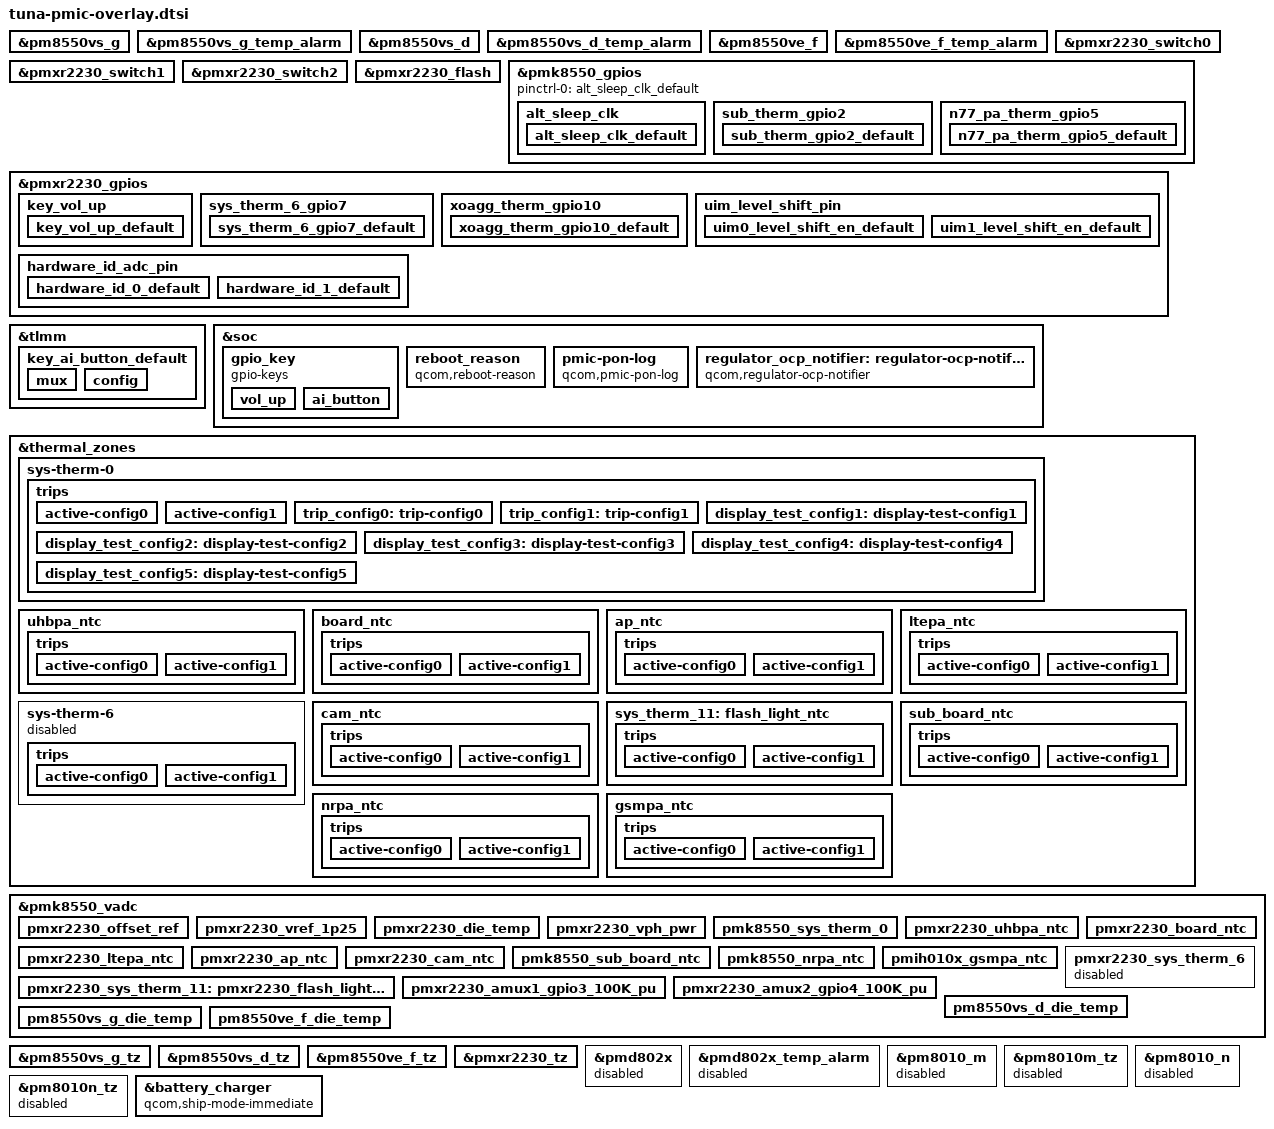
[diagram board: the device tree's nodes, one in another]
// SPDX-License-Identifier: BSD-3-Clause
/*
 * Copyright (c) 2024-2025, Qualcomm Innovation Center, Inc. All rights reserved.
 */

#include <dt-bindings/gpio/gpio.h>
#include <dt-bindings/iio/qcom,spmi-adc5-gen3-pmxr2230.h>
#include <dt-bindings/iio/qcom,spmi-adc5-gen4-pmih010x.h>

#include "pmk8550.dtsi"
#include "pmxr2230.dtsi"
#include "pm8550vs.dtsi"
#include "pmr735d.dtsi"
#include "pm8550ve.dtsi"
#include "pm8010.dtsi"
#include "pmd802x.dtsi"

&pm8550vs_g {
	status = "ok";
};

&pm8550vs_g_temp_alarm {
	status = "ok";
};

&pm8550vs_d {
	status = "ok";
};

&pm8550vs_d_temp_alarm {
	status = "ok";
};

&pm8550ve_f {
	status = "ok";
};

&pm8550ve_f_temp_alarm {
	status = "ok";
};

&pmxr2230_switch0 {
	qcom,led-mask = <9>; /* Channels 1 & 4 */
	qcom,symmetry-en;
};

&pmxr2230_switch1 {
	qcom,led-mask = <6>; /* Channels 2 & 3 */
	qcom,symmetry-en;
};

&pmxr2230_switch2 {
	qcom,led-mask = <15>; /* All Channels */
	qcom,symmetry-en;
};

&pmxr2230_flash {
	status = "ok";
};

&pmk8550_gpios {
	pinctrl-0 = <&alt_sleep_clk_default>;
	pinctrl-names = "default";

	alt_sleep_clk {
		alt_sleep_clk_default: alt_sleep_clk_default {
			pins = "gpio3";
			function = "func1";
			input-disable;
			output-enable;
			bias-disable;
			power-source = <0>;
		};
	};

	sub_therm_gpio2 {
		sub_therm_gpio2_default: sub_therm_gpio2_default {
			pins = "gpio2";
			bias-high-impedance;
		};
	};

	n77_pa_therm_gpio5 {
		n77_pa_therm_gpio5_default: n77_pa_therm_gpio5_default {
			pins = "gpio5";
			bias-high-impedance;
		};
	};
};

&pmxr2230_gpios {
	pinctrl-names = "default";
	pinctrl-0 = <&uim0_level_shift_en_default
				 &uim1_level_shift_en_default>;

	key_vol_up {
		key_vol_up_default: key_vol_up_default {
			pins = "gpio6";
			function = "normal";
			input-enable;
			bias-pull-up;
			power-source = <1>;
		};
	};

	sys_therm_6_gpio7 {
		sys_therm_6_gpio7_default: sys_therm_6_gpio7_default {
			pins = "gpio7";
			bias-high-impedance;
		};
	};

	xoagg_therm_gpio10 {
		xoagg_therm_gpio10_default: xoagg_therm_gpio10_default {
			pins = "gpio10";
			bias-high-impedance;
		};
	};

	uim_level_shift_pin {
		uim0_level_shift_en_default: uim0_level_shift_en_default {
			pins = "gpio1";
			function = "normal";
			power-source = <1>;
			bias-disable;
			input-disable;
			output-high;
		};
		uim1_level_shift_en_default: uim1_level_shift_en_default {
			pins = "gpio2";
			function = "normal";
			power-source = <1>;
			bias-disable;
			input-disable;
			output-high;
		 };
	};

	hardware_id_adc_pin {
		/* HWID ID_0: Build ID */
		hardware_id_0_default: hardware_id_0_default {
			pins = "gpio4";
			bias-high-impedance;
		};
		/* HWID ID_1: Project ID */
		hardware_id_1_default: hardware_id_1_default {
			pins = "gpio3";
			bias-high-impedance;
		};
	};
};

&tlmm {
	key_ai_button_default: key_ai_button_default {
		mux {
			pins = "gpio78";
			function = "gpio";
		};

		config {
			pins = "gpio78";
			bias-pull-up;
			input-enable;
		};
	};
};

&soc {
	gpio_key {
		compatible = "gpio-keys";
		label = "gpio-keys";
		pinctrl-names = "default";
		pinctrl-0 = <&key_vol_up_default &key_ai_button_default>;
		vol_up {
			label = "volume_up";
			gpios = <&pmxr2230_gpios 6 GPIO_ACTIVE_LOW>;
			linux,input-type = <1>;
			linux,code = <KEY_VOLUMEUP>;
			gpio-key,wakeup;
			debounce-interval = <15>;
			linux,can-disable;
		};

		ai_button {
			label = "ai_button";
			gpios = <&tlmm 78 GPIO_ACTIVE_LOW>;
			linux,input-type = <1>;
			linux,code = <250>; /* KEY_AI */
			gpio-key,wakeup;
			debounce-interval = <15>;
			linux,can-disable;
		};
	};

	reboot_reason {
		compatible = "qcom,reboot-reason";
		nvmem-cells = <&restart_reason>;
		nvmem-cell-names = "restart_reason";
	};

	pmic-pon-log {
		compatible = "qcom,pmic-pon-log";
		nvmem = <&pmk8550_sdam_5>, <&pmk8550_sdam_6>;
		nvmem-names = "pon_log0", "pon_log1";
		depends-on-supply = <&gh_watchdog>;
	};

	regulator_ocp_notifier: regulator-ocp-notifier {
		compatible = "qcom,regulator-ocp-notifier";
		interrupt-parent = <&spmi_bus>;
		interrupts = <0x0 0x71 0x1 IRQ_TYPE_EDGE_RISING>;
		nvmem-cells = <&ocp_log>;
		nvmem-cell-names = "ocp_log";
	};
};

&thermal_zones {
	sys-therm-0 {
		polling-delay-passive = <5000>;
		polling-delay = <0>;
		thermal-sensors = <&pmk8550_vadc PMK8550_ADC5_GEN3_AMUX_THM1_XO_THERM_100K_PU>;
		trips {
			active-config0 {
				temperature = <125000>;
				hysteresis = <1000>;
				type = "passive";
			};

			active-config1 {
				temperature = <125000>;
				hysteresis = <1000>;
				type = "passive";
			};

			trip_config0: trip-config0 {
				temperature = <78000>;
				hysteresis = <8000>;
				type = "passive";
			};

			trip_config1: trip-config1 {
				temperature = <80000>;
				hysteresis = <10000>;
				type = "passive";
			};

			display_test_config1: display-test-config1 {
				temperature = <125000>;
				hysteresis = <1000>;
				type = "passive";
			};

			display_test_config2: display-test-config2 {
				temperature = <125000>;
				hysteresis = <1000>;
				type = "passive";
			};

			display_test_config3: display-test-config3 {
				temperature = <125000>;
				hysteresis = <1000>;
				type = "passive";
			};

			display_test_config4: display-test-config4 {
				temperature = <125000>;
				hysteresis = <1000>;
				type = "passive";
			};

			display_test_config5: display-test-config5 {
				temperature = <125000>;
				hysteresis = <1000>;
				type = "passive";
			};
		};
	};

	/*Nothing add NTC driver: add thermal_zone start*/
	uhbpa_ntc {
		polling-delay-passive = <0>;
		polling-delay = <0>;
		thermal-sensors = <&pmk8550_vadc PMXR2230_ADC5_GEN3_AMUX_THM1_100K_PU>;
		trips {
			active-config0 {
				temperature = <125000>;
				hysteresis = <1000>;
				type = "passive";
			};

			active-config1 {
				temperature = <125000>;
				hysteresis = <1000>;
				type = "passive";
			};
		};
	};

	board_ntc {
		polling-delay-passive = <0>;
		polling-delay = <0>;
		thermal-sensors = <&pmk8550_vadc PMXR2230_ADC5_GEN3_AMUX_THM4_100K_PU>;
		trips {
			active-config0 {
				temperature = <125000>;
				hysteresis = <1000>;
				type = "passive";
			};

			active-config1 {
				temperature = <125000>;
				hysteresis = <1000>;
				type = "passive";
			};
		};
	};

	ap_ntc {
		polling-delay-passive = <0>;
		polling-delay = <0>;
		thermal-sensors = <&pmk8550_vadc PMXR2230_ADC5_GEN3_AMUX_THM2_100K_PU>;
		trips {
			active-config0 {
				temperature = <125000>;
				hysteresis = <1000>;
				type = "passive";
			};

			active-config1 {
				temperature = <125000>;
				hysteresis = <1000>;
				type = "passive";
			};
		};
	};

	ltepa_ntc {
		polling-delay-passive = <0>;
		polling-delay = <0>;
		thermal-sensors = <&pmk8550_vadc PMXR2230_ADC5_GEN3_AMUX_THM3_100K_PU>;
		trips {
			active-config0 {
				temperature = <125000>;
				hysteresis = <1000>;
				type = "passive";
			};

			active-config1 {
				temperature = <125000>;
				hysteresis = <1000>;
				type = "passive";
			};
		};
	};

	sys-therm-6 {
		status = "disabled";
		polling-delay-passive = <0>;
		polling-delay = <0>;
		thermal-sensors = <&pmk8550_vadc PMXR2230_ADC5_GEN3_AMUX3_GPIO7_100K_PU>;
		trips {
			active-config0 {
				temperature = <125000>;
				hysteresis = <1000>;
				type = "passive";
			};

			active-config1 {
				temperature = <125000>;
				hysteresis = <1000>;
				type = "passive";
			};
		};
	};

	cam_ntc {
		polling-delay-passive = <0>;
		polling-delay = <0>;
		thermal-sensors = <&pmk8550_vadc PMXR2230_ADC5_GEN3_AMUX4_GPIO10_100K_PU>;
		trips {
			active-config0 {
				temperature = <125000>;
				hysteresis = <1000>;
				type = "passive";
			};

			active-config1 {
				temperature = <125000>;
				hysteresis = <1000>;
				type = "passive";
			};
		};
	};

	sys_therm_11: flash_light_ntc {
		polling-delay-passive = <0>;
		polling-delay = <0>;
		thermal-sensors = <&pmk8550_vadc PMXR2230_ADC5_GEN3_AMUX_THM5_100K_PU>;
		trips {
			active-config0 {
				temperature = <125000>;
				hysteresis = <1000>;
				type = "passive";
			};

			active-config1 {
				temperature = <125000>;
				hysteresis = <1000>;
				type = "passive";
			};
		};
	};

	sub_board_ntc {
		polling-delay-passive = <0>;
		polling-delay = <0>;
		thermal-sensors = <&pmk8550_vadc PMK8550_ADC5_GEN3_AMUX_THM3_GPIO2_100K_PU>;
		trips {
			active-config0 {
				temperature = <125000>;
				hysteresis = <1000>;
				type = "passive";
			};

			active-config1 {
				temperature = <125000>;
				hysteresis = <1000>;
				type = "passive";
			};
		};
	};

	nrpa_ntc {
		polling-delay-passive = <0>;
		polling-delay = <0>;
		thermal-sensors = <&pmk8550_vadc PMK8550_ADC5_GEN3_AMUX_THM6_GPIO5_100K_PU>;
		trips {
			active-config0 {
				temperature = <125000>;
				hysteresis = <1000>;
				type = "passive";
			};

			active-config1 {
				temperature = <125000>;
				hysteresis = <1000>;
				type = "passive";
			};
		};
	};

	gsmpa_ntc {
		polling-delay-passive = <0>;
		polling-delay = <0>;
		thermal-sensors = <&pmk8550_vadc PMIH010X_ADC5_GEN4_AMUX2_BAT2_ID_100K_PU>;
		trips {
			active-config0 {
				temperature = <125000>;
				hysteresis = <1000>;
				type = "passive";
			};

			active-config1 {
				temperature = <125000>;
				hysteresis = <1000>;
				type = "passive";
			};
		};
	};
	/*Nothing add NTC driver: add thermal_zone end*/
};

&pmk8550_vadc {
	pinctrl-names = "default";
	pinctrl-0 = <&sys_therm_6_gpio7_default
				 &hardware_id_0_default
				 &hardware_id_1_default
				 &sub_therm_gpio2_default
				 &n77_pa_therm_gpio5_default
				 &xoagg_therm_gpio10_default>;

	/delete-node/ pm8550_offset_ref;
	/delete-node/ pm8550_vref_1p25;
	/delete-node/ pm8550_die_temp;
	/delete-node/ pm8550_vph_pwr;

	/* PMXR2230 Channel nodes */
	pmxr2230_offset_ref {
		reg = <PMXR2230_ADC5_GEN3_OFFSET_REF>;
		label = "pmxr2230_offset_ref";
		qcom,pre-scaling = <1 1>;
	};

	pmxr2230_vref_1p25 {
		reg = <PMXR2230_ADC5_GEN3_1P25VREF>;
		label = "pmxr2230_vref_1p25";
		qcom,pre-scaling = <1 1>;
	};

	pmxr2230_die_temp {
		reg = <PMXR2230_ADC5_GEN3_DIE_TEMP>;
		label = "pmxr2230_die_temp";
		qcom,pre-scaling = <1 1>;
	};

	pmxr2230_vph_pwr {
		reg = <PMXR2230_ADC5_GEN3_VPH_PWR>;
		label = "pmxr2230_vph_pwr";
		qcom,pre-scaling = <1 3>;
	};

	pmk8550_sys_therm_0 {
		reg = <PMK8550_ADC5_GEN3_AMUX_THM1_XO_THERM_100K_PU>;
		label = "pmk8550_sys_therm_0";
		qcom,ratiometric;
		qcom,hw-settle-time = <200>;
		qcom,pre-scaling = <1 1>;
		qcom,adc-tm-type = <1>;
	};

	/*Nothing add NTC driver: add vadc start*/
	pmxr2230_uhbpa_ntc {
		reg = <PMXR2230_ADC5_GEN3_AMUX_THM1_100K_PU>;
		label = "pmxr2230_uhbpa_ntc";
		qcom,ratiometric;
		qcom,hw-settle-time = <200>;
		qcom,pre-scaling = <1 1>;
		qcom,adc-tm-type = <1>;
	};

	pmxr2230_board_ntc {
		reg = <PMXR2230_ADC5_GEN3_AMUX_THM4_100K_PU>;
		label = "pmxr2230_board_ntc";
		qcom,ratiometric;
		qcom,hw-settle-time = <200>;
		qcom,pre-scaling = <1 1>;
		qcom,adc-tm-type = <1>;
	};

	pmxr2230_ltepa_ntc {
		reg = <PMXR2230_ADC5_GEN3_AMUX_THM3_100K_PU>;
		label = "pmxr2230_ltepa_ntc";
		qcom,ratiometric;
		qcom,hw-settle-time = <200>;
		qcom,pre-scaling = <1 1>;
		qcom,adc-tm-type = <1>;
	};

	pmxr2230_ap_ntc {
		reg = <PMXR2230_ADC5_GEN3_AMUX_THM2_100K_PU>;
		label = "pmxr2230_ap_ntc";
		qcom,ratiometric;
		qcom,hw-settle-time = <200>;
		qcom,pre-scaling = <1 1>;
		qcom,adc-tm-type = <1>;
	};

	pmxr2230_cam_ntc {
		reg = <PMXR2230_ADC5_GEN3_AMUX4_GPIO10_100K_PU>;
		label = "pmxr2230_cam_ntc";
		qcom,ratiometric;
		qcom,hw-settle-time = <200>;
		qcom,pre-scaling = <1 1>;
		qcom,adc-tm-type = <1>;
	};

	pmk8550_sub_board_ntc {
		reg = <PMK8550_ADC5_GEN3_AMUX_THM3_GPIO2_100K_PU>;
		label = "pmk8550_sub_board_ntc";
		qcom,ratiometric;
		qcom,hw-settle-time = <200>;
		qcom,pre-scaling = <1 1>;
		qcom,adc-tm-type = <1>;
	};

	pmk8550_nrpa_ntc {
		reg = <PMK8550_ADC5_GEN3_AMUX_THM6_GPIO5_100K_PU>;
		label = "pmk8550_nrpa_ntc";
		qcom,ratiometric;
		qcom,hw-settle-time = <200>;
		qcom,pre-scaling = <1 1>;
		qcom,adc-tm-type = <1>;
	};

	pmih010x_gsmpa_ntc {
		reg = <PMIH010X_ADC5_GEN4_AMUX2_BAT2_ID_100K_PU>;
		label = "pmih010x_gsmpa_ntc";
		qcom,ratiometric;
		qcom,pre-scaling = <1 1>;
		qcom,adc-tm-type = <1>;
		qcom,adc5-gen4;
	};
	/*Nothing add NTC driver: add vadc end*/

	pmxr2230_sys_therm_6 {
		status = "disabled";
		reg = <PMXR2230_ADC5_GEN3_AMUX3_GPIO7_100K_PU>;
		label = "pmxr2230_sys_therm_6";
		qcom,ratiometric;
		qcom,hw-settle-time = <200>;
		qcom,pre-scaling = <1 1>;
		qcom,adc-tm-type = <1>;
	};

	pmxr2230_sys_therm_11: pmxr2230_flash_light_ntc {
		reg = <PMXR2230_ADC5_GEN3_AMUX_THM5_100K_PU>;
		label = "pmxr2230_sys_therm_11";
		qcom,ratiometric;
		qcom,hw-settle-time = <200>;
		qcom,pre-scaling = <1 1>;
		qcom,adc-tm-type = <1>;
	};
	//#endif

	pmxr2230_amux1_gpio3_100K_pu {
		reg = <PMXR2230_ADC5_GEN3_AMUX1_GPIO3_100K_PU>;
		label = "pmxr2230_amux1_gpio3_100K_pu";
		qcom,pre-scaling = <1 1>;
	};

	pmxr2230_amux2_gpio4_100K_pu {
		reg = <PMXR2230_ADC5_GEN3_AMUX2_GPIO4_100K_PU>;
		label = "pmxr2230_amux2_gpio4_100K_pu";
		qcom,pre-scaling = <1 1>;
	};

	pm8550vs_d_die_temp {
		reg = <PM8550VX_ADC5_GEN3_DIE_TEMP(3)>;
		label = "pm8550vs_d_die_temp";
		qcom,pre-scaling = <1 1>;
	};

	pm8550vs_g_die_temp {
		reg = <PM8550VX_ADC5_GEN3_DIE_TEMP(6)>;
		label = "pm8550vs_g_die_temp";
		qcom,pre-scaling = <1 1>;
	};

	pm8550ve_f_die_temp: pm8550ve_f_die_temp {
		reg = <PM8550VX_ADC5_GEN3_DIE_TEMP(5)>;
		label = "pm8550ve_f_die_temp";
		qcom,pre-scaling = <1 1>;
	};

};

&pm8550vs_g_tz {
	io-channels = <&pmk8550_vadc PM8550VX_ADC5_GEN3_DIE_TEMP(6)>;
	io-channel-names = "thermal";
};

&pm8550vs_d_tz {
	io-channels = <&pmk8550_vadc PM8550VX_ADC5_GEN3_DIE_TEMP(3)>;
	io-channel-names = "thermal";
};

&pm8550ve_f_tz {
	io-channels = <&pmk8550_vadc PM8550VX_ADC5_GEN3_DIE_TEMP(5)>;
	io-channel-names = "thermal";
};

&pmxr2230_tz {
	io-channels = <&pmk8550_vadc PMXR2230_ADC5_GEN3_DIE_TEMP>;
	io-channel-names = "thermal";
};

/* !!disable the following PMICs and TZs due to not supported by hardware */
&pmd802x {
	status = "disabled";
};

&pmd802x_temp_alarm {
	status = "disabled";
};

&pm8010_m {
	status = "disabled";
};

&pm8010m_tz {
	status = "disabled";
};

&pm8010_n {
	status = "disabled";
};

&pm8010n_tz {
	status = "disabled";
};
/* !!disable the PMICs and TZs due to not supported by hardware end */
&battery_charger {
	qcom,ship-mode-immediate;
};
